# R7KA8M2AD register map
Vendor: Renesas Electronics Corporation; Series: RA8; File version: 1.10.02
CPU: CM85 r0p2, little endian, MPU, FPU, VTOR, 4 interrupt priority bits, 96 interrupts
Registers are 32-bit, read-write, reset 0x0 unless marked. A register's access mark holds for its fields unless they carry their own. Offsets are from the block's base; [hi:lo] are bit positions; {n}, {i} and the like mark numbered series; 'fields as' and 'values as' point back to an identical list.

## ECCMB0
Base 0x4036F200
Same registers: ECCMB1 0x4036F300, ECCMB0_NS 0x5036F200, ECCMB1_NS 0x5036F300
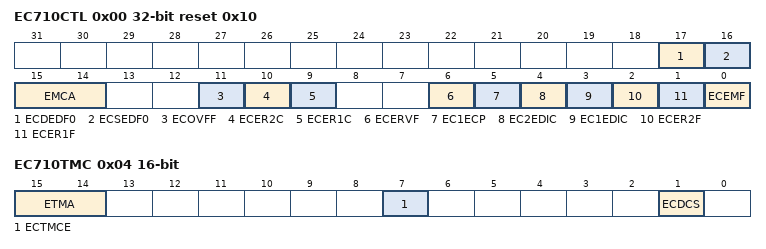
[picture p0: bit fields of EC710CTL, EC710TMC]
0x00 EC710CTL reset 0x10 — ECC Control Register
  [17] ECDEDF0 ro — ECC Dual Bit Error Address Detection Flag
    0=There is no bit error in EC710EAD0 after reset or clearing ECER2F bit; 1=Address captured in EC710EAD0 shows that 2-bit error occurred and captured
  [16] ECSEDF0 ro — ECC Single bit Error Address Detection Flag
    0=There is no bit error in EC710EAD0 after reset or clearing ECER1F bit; 1=Address captured in EC710EAD0 shows that 1-bit error occurred and captured
  [15:14] EMCA — Access Control to ECC Mode Select bit
  [11] ECOVFF ro — ECC Overflow Detection Flag
    0=No effect; 1=ECC overflow detection flag
  [10] ECER2C — 2-bit ECC Error Detection Flag Clear
    0=No effect; 1=Clear 2-bit ECC error detection flag
  [9] ECER1C — Accumulating ECC Error Detection and Correction Flag Clear
    0=No effect; 1=Clear accumulating ECC error detection and correction flag
  [6] ECERVF — ECC Error Judgment Enable Flag
    0=Error judgment disable; 1=Error judgment enable
  [5] EC1ECP — ECC 1-bit Error Correction Permission
    0=At 1-bit error detection, the error correction is executed; 1=At 1-bit error detection, the error correction is not executed
  [4] EC2EDIC — ECC 2-bit Error Detection Interrupt Control
    0=Disable 2-bit error detection interrupt request; 1=Enable 2-bit error detection interrupt request
  [3] EC1EDIC — ECC 1-bit Error Detection Interrupt Control
    0=Disable 1-bit error detection interrupt request; 1=Enable 1-bit error detection interrupt request
  [2] ECER2F ro — 2-bit ECC Error Detection Flag
    0=After clearing this bit, 2-bit error has not occurred; 1=2-bit error has occurred
  [1] ECER1F ro — ECC Error Detection and Correction Flag
    0=After clearing this bit, 1-bit error correction has not occurred; 1=1-bit error has occurred
  [0] ECEMF ro — ECC Error Message Flag
    0=There is no bit error in present RAM output data; 1=There is bit error in present RAM output data
0x04 EC710TMC 16-bit — ECC Test Mode Control Register
  [15:14] ETMA — ECC Test Mode Bit Access Control
  [7] ECTMCE — ECC Test Mode Control Enable
    0=The access to test mode register and bit is disabled; 1=The access to test mode register and bit is enabled
  [1] ECDCS — ECC Decode Input Select
    0=Input lower 32 bits of RAM output data to data area of decode circuit; 1=Input ECEDB31-0 in EC710TED register to data area of decode circuit
0x0C EC710TED — ECC Test Substitute Data Register
  [31:0] ECEDB — ECC Test Substitute Data
0x10 EC710EAD0 ro — ECC Error Address Register
  [9:0] ECEAD — ECC Error Address

## PORT0 — Pmn Pin FunctionPort 0 Control RegistersPmn Pin Function Control Register
Base 0x40400000
Same registers: PORT5 0x404000A0, PORT6 0x404000C0, PORT7 0x404000E0, PORT8 0x40400100, PORT9 0x40400120, PORTA 0x40400140, PORTB 0x40400160, PORTC 0x40400180, PORTD 0x404001A0, PORT0_NS 0x50400000, PORT5_NS 0x504000A0, PORT6_NS 0x504000C0, PORT7_NS 0x504000E0, PORT8_NS 0x50400100, PORT9_NS 0x50400120, PORTA_NS 0x50400140, PORTB_NS 0x50400160, PORTC_NS 0x50400180, PORTD_NS 0x504001A0
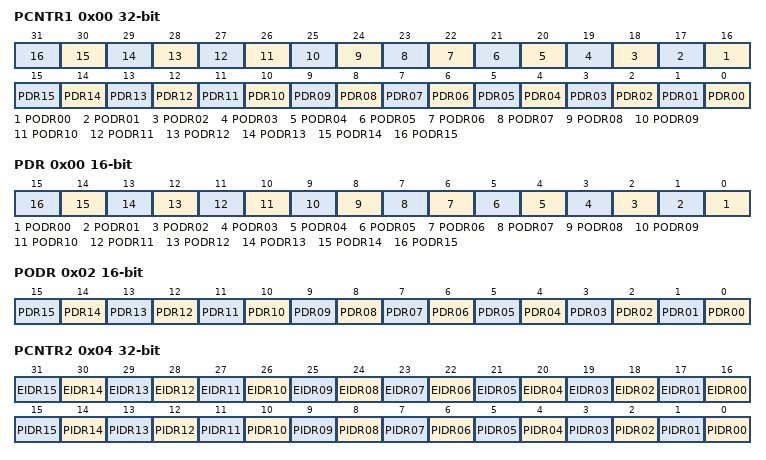
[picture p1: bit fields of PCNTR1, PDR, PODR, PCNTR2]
0x00 PCNTR1 — Port Control Register 1
  [n+16] PODR{n:02} (n=0..15) — Pmn Output Data
    0=Low output; 1=High output
  [n] PDR{n:02} (n=0..15) — Pmn Direction
    0=Input (functions as an input pin); 1=Output (functions as an output pin)
0x00 PDR 16-bit (alternate view of PCNTR1) — Port Control Register 1
  [all] fields
    0=Low output; 1=High output
  [n] PODR{n:02} (n=0..15) — Pmn Output Data
0x02 PODR 16-bit (alternate view of PCNTR1) — Port Control Register 1
  [all] fields
    values as PCNTR1.PDR00
  [n] PDR{n:02} (n=0..15) — Pmn Direction
0x04 PCNTR2 ro (reset mask 0xFFFF0000) — Port Control Register 2
  [n+16] EIDR{n:02} (n=0..15) — Port Event Input Data
    0=Low input; 1=High input
  [n] PIDR{n:02} (n=0..15) — Pmn State
    0=Low level; 1=High level
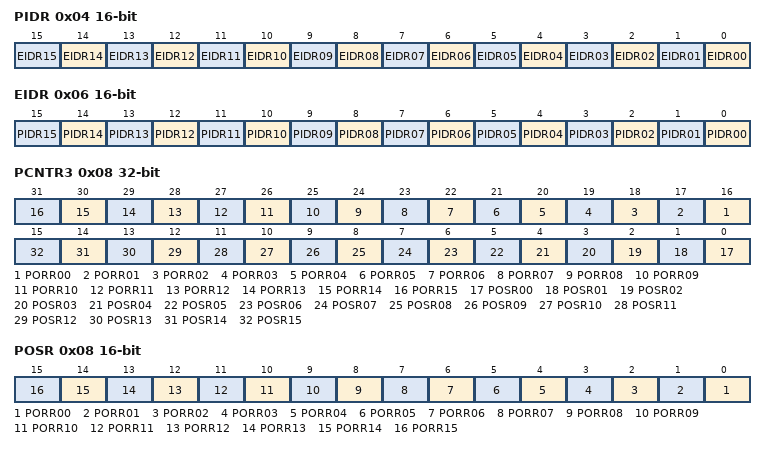
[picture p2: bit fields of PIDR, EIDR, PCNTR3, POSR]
0x04 PIDR 16-bit ro (alternate view of PCNTR2) — Port Control Register 2
  [all] fields
    0=Low input; 1=High input
  [n] EIDR{n:02} (n=0..15) — Port Event Input Data
0x06 EIDR 16-bit ro reset not defined (alternate view of PCNTR2) — Port Control Register 2
  [all] fields
    0=Low level; 1=High level
  [n] PIDR{n:02} (n=0..15) — Pmn State
0x08 PCNTR3 wo — Port Control Register 3
  [n+16] PORR{n:02} (n=0..15) — Pmn Output Reset
    0=No effect on output; 1=Low output
  [n] POSR{n:02} (n=0..15) — Pmn Output Set
    0=No effect on output; 1=High output
0x08 POSR 16-bit wo (alternate view of PCNTR3) — Port Control Register 3
  [all] fields
    0=No effect on output; 1=Low output
  [n] PORR{n:02} (n=0..15) — Pmn Output Reset
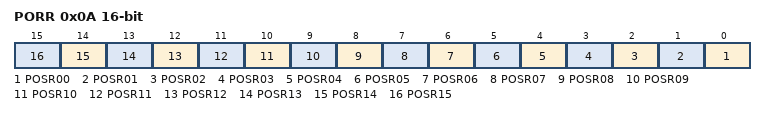
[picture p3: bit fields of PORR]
0x0A PORR 16-bit wo (alternate view of PCNTR3) — Port Control Register 3
  [all] fields
    0=No effect on output; 1=High output
  [n] POSR{n:02} (n=0..15) — Pmn Output Set

## PORT1 — Pmn Pin FunctionPort 1 Control RegistersPmn Pin Function Control Register
Base 0x40400020
Same registers: PORT2 0x40400040, PORT3 0x40400060, PORT4 0x40400080, PORT1_NS 0x50400020, PORT2_NS 0x50400040, PORT3_NS 0x50400060, PORT4_NS 0x50400080
Registers as PORT0; these are added or differ:
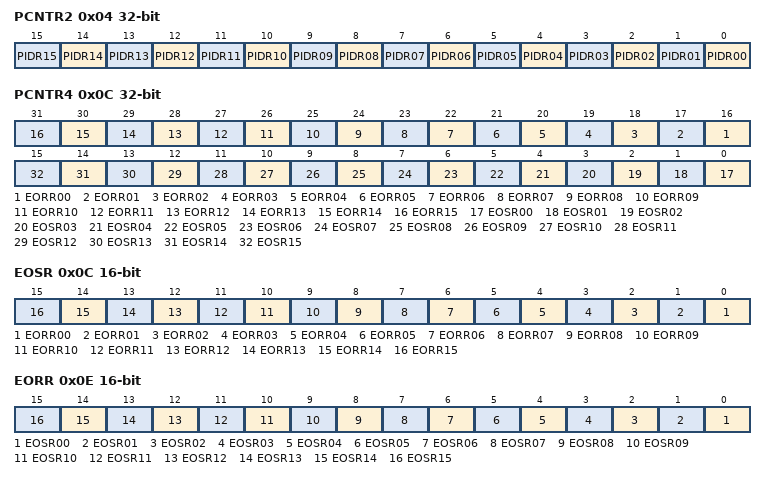
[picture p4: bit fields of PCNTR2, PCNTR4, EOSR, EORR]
0x04 PCNTR2 ro (reset mask 0xFFFF0000) — Port Control Register 2
  [all] fields
    0=Low level; 1=High level
  [n] PIDR{n:02} (n=0..15) — Pmn State
0x04 PIDR 16-bit ro (alternate view of PCNTR2) — Port Control Register 2
0x0C PCNTR4 — Port Control Register 4
  [n+16] EORR{n:02} (n=0..15) — Pmn Event Output Reset
    0=No effect on output; 1=Low output
  [n] EOSR{n:02} (n=0..15) — Pmn Event Output Set
    0=No effect on output; 1=High output
0x0C EOSR 16-bit (alternate view of PCNTR4) — Port Control Register 4
  [all] fields
    0=No effect on output; 1=Low output
  [n] EORR{n:02} (n=0..15) — Pmn Event Output Reset
0x0E EORR 16-bit (alternate view of PCNTR4) — Port Control Register 4
  [all] fields
    0=No effect on output; 1=High output
  [n] EOSR{n:02} (n=0..15) — Pmn Event Output Set
